# ESP32-H4 register map
Vendor: ESPRESSIF SYSTEMS (SHANGHAI) CO., LTD.; Series: ESP32 H-Series; File version: 1
CPU: RV32IMAC r0p0, little endian, no MPU, no FPU, 0 interrupt priority bits
Address unit: 32 bits
Registers are 32-bit, read-write, reset 0x0 unless marked. A register's access mark holds for its fields unless they carry their own. Offsets are from the block's base; [hi:lo] are bit positions.

## PMU — PMU Peripheral
Base 0x600B2400
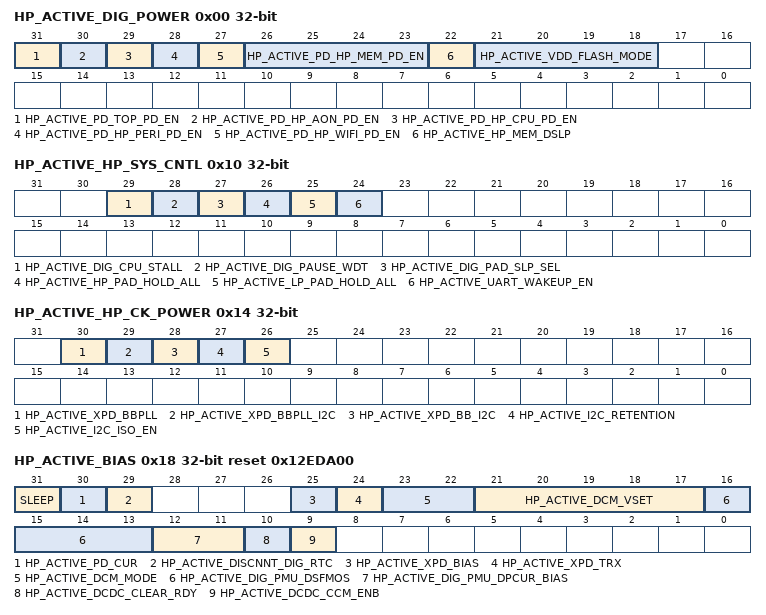
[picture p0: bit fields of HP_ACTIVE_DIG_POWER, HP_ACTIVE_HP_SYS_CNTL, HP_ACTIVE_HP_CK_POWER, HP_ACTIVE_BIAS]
0x00 HP_ACTIVE_DIG_POWER — need_des
  [31] HP_ACTIVE_PD_TOP_PD_EN — need_des
  [30] HP_ACTIVE_PD_HP_AON_PD_EN — need_des
  [29] HP_ACTIVE_PD_HP_CPU_PD_EN — need_des
  [28] HP_ACTIVE_PD_HP_PERI_PD_EN — need_des
  [27] HP_ACTIVE_PD_HP_WIFI_PD_EN — need_des
  [26:23] HP_ACTIVE_PD_HP_MEM_PD_EN — need_des
  [22] HP_ACTIVE_HP_MEM_DSLP — need_des
  [21:18] HP_ACTIVE_VDD_FLASH_MODE — need_des
0x04 HP_ACTIVE_ICG_HP_FUNC reset 0xFFFFFFFF — need_des
  [31:0] HP_ACTIVE_DIG_ICG_FUNC_EN
0x08 HP_ACTIVE_ICG_HP_APB reset 0xFFFFFFFF — need_des
  [31:0] HP_ACTIVE_DIG_ICG_APB_EN
0x0C HP_ACTIVE_ICG_MODEM — need_des
  [31:30] HP_ACTIVE_DIG_ICG_MODEM_CODE
0x10 HP_ACTIVE_HP_SYS_CNTL — need_des
  [29] HP_ACTIVE_DIG_CPU_STALL — need_des
  [28] HP_ACTIVE_DIG_PAUSE_WDT — need_des
  [27] HP_ACTIVE_DIG_PAD_SLP_SEL — need_des
  [26] HP_ACTIVE_HP_PAD_HOLD_ALL — need_des
  [25] HP_ACTIVE_LP_PAD_HOLD_ALL — need_des
  [24] HP_ACTIVE_UART_WAKEUP_EN — need_des
0x14 HP_ACTIVE_HP_CK_POWER — need_des
  [30] HP_ACTIVE_XPD_BBPLL — need_des
  [29] HP_ACTIVE_XPD_BBPLL_I2C — need_des
  [28] HP_ACTIVE_XPD_BB_I2C — need_des
  [27] HP_ACTIVE_I2C_RETENTION — need_des
  [26] HP_ACTIVE_I2C_ISO_EN — need_des
0x18 HP_ACTIVE_BIAS reset 0x12EDA00 — need_des
  [31] SLEEP — need_des
  [30] HP_ACTIVE_PD_CUR — need_des
  [29] HP_ACTIVE_DISCNNT_DIG_RTC — need_des
  [25] HP_ACTIVE_XPD_BIAS — need_des
  [24] HP_ACTIVE_XPD_TRX — need_des
  [23:22] HP_ACTIVE_DCM_MODE — need_des
  [21:17] HP_ACTIVE_DCM_VSET — need_des
  [16:13] HP_ACTIVE_DIG_PMU_DSFMOS — need_des
  [12:11] HP_ACTIVE_DIG_PMU_DPCUR_BIAS — need_des
  [10] HP_ACTIVE_DCDC_CLEAR_RDY — need_des
  [9] HP_ACTIVE_DCDC_CCM_ENB — need_des
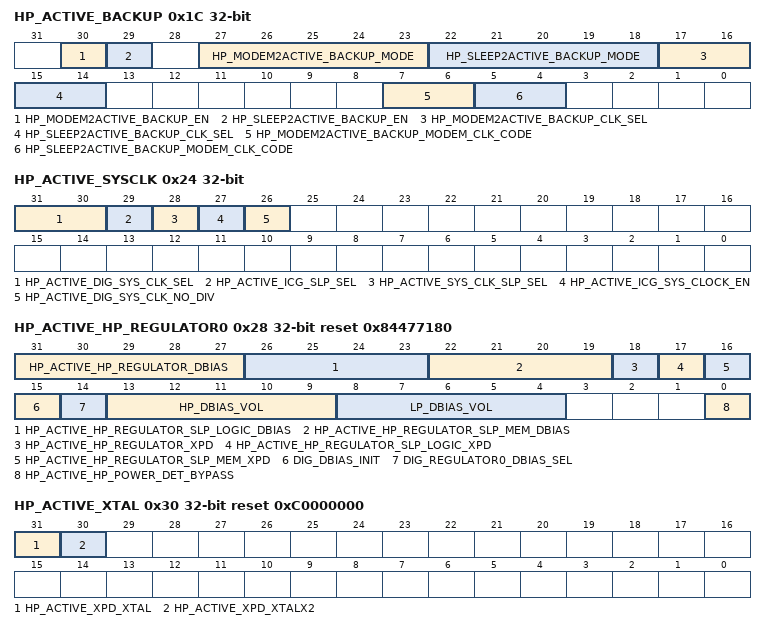
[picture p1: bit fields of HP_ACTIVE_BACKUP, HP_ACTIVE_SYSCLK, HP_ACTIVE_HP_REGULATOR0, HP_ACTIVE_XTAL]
0x1C HP_ACTIVE_BACKUP — need_des
  [30] HP_MODEM2ACTIVE_BACKUP_EN — need_des
  [29] HP_SLEEP2ACTIVE_BACKUP_EN — need_des
  [27:23] HP_MODEM2ACTIVE_BACKUP_MODE — need_des
  [22:18] HP_SLEEP2ACTIVE_BACKUP_MODE — need_des
  [17:16] HP_MODEM2ACTIVE_BACKUP_CLK_SEL — need_des
  [15:14] HP_SLEEP2ACTIVE_BACKUP_CLK_SEL — need_des
  [7:6] HP_MODEM2ACTIVE_BACKUP_MODEM_CLK_CODE — need_des
  [5:4] HP_SLEEP2ACTIVE_BACKUP_MODEM_CLK_CODE — need_des
0x20 HP_ACTIVE_BACKUP_CLK — need_des
  [31:0] HP_ACTIVE_BACKUP_ICG_FUNC_EN
0x24 HP_ACTIVE_SYSCLK — need_des
  [31:30] HP_ACTIVE_DIG_SYS_CLK_SEL — need_des
  [29] HP_ACTIVE_ICG_SLP_SEL — need_des
  [28] HP_ACTIVE_SYS_CLK_SLP_SEL — need_des
  [27] HP_ACTIVE_ICG_SYS_CLOCK_EN — need_des
  [26] HP_ACTIVE_DIG_SYS_CLK_NO_DIV — need_des
0x28 HP_ACTIVE_HP_REGULATOR0 access per field reset 0x84477180 — need_des
  [31:27] HP_ACTIVE_HP_REGULATOR_DBIAS rw — need_des
  [26:23] HP_ACTIVE_HP_REGULATOR_SLP_LOGIC_DBIAS rw — need_des
  [22:19] HP_ACTIVE_HP_REGULATOR_SLP_MEM_DBIAS rw — need_des
  [18] HP_ACTIVE_HP_REGULATOR_XPD rw — need_des
  [17] HP_ACTIVE_HP_REGULATOR_SLP_LOGIC_XPD rw — need_des
  [16] HP_ACTIVE_HP_REGULATOR_SLP_MEM_XPD rw — need_des
  [15] DIG_DBIAS_INIT wo — need_des
  [14] DIG_REGULATOR0_DBIAS_SEL rw — need_des
  [13:9] HP_DBIAS_VOL ro — need_des
  [8:4] LP_DBIAS_VOL ro — need_des
  [0] HP_ACTIVE_HP_POWER_DET_BYPASS rw — need_des
0x2C HP_ACTIVE_HP_REGULATOR1 reset 0x1000 — need_des
  [31:8] HP_ACTIVE_HP_REGULATOR_DRV_B
0x30 HP_ACTIVE_XTAL reset 0xC0000000 — need_des
  [31] HP_ACTIVE_XPD_XTAL — need_des
  [30] HP_ACTIVE_XPD_XTALX2 — need_des
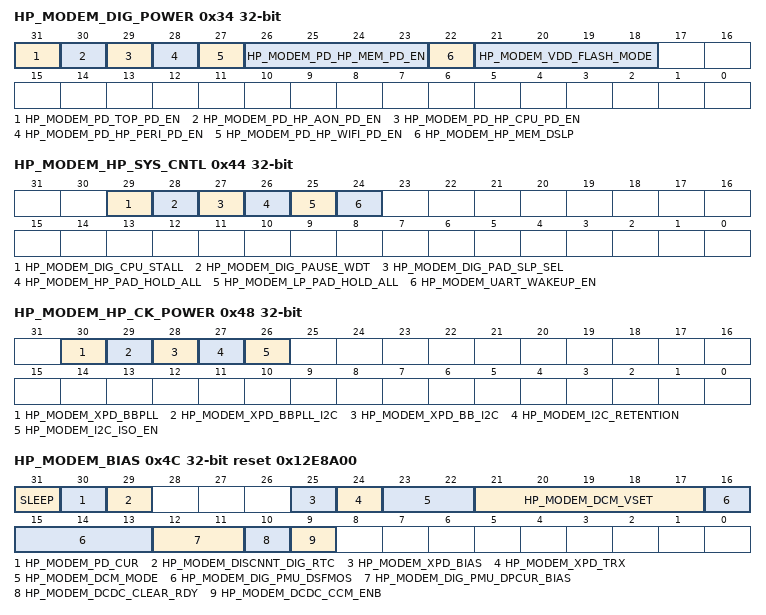
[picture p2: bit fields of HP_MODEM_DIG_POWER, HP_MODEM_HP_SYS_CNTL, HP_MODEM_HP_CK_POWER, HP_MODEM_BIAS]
0x34 HP_MODEM_DIG_POWER — need_des
  [31] HP_MODEM_PD_TOP_PD_EN — need_des
  [30] HP_MODEM_PD_HP_AON_PD_EN — need_des
  [29] HP_MODEM_PD_HP_CPU_PD_EN — need_des
  [28] HP_MODEM_PD_HP_PERI_PD_EN — need_des
  [27] HP_MODEM_PD_HP_WIFI_PD_EN — need_des
  [26:23] HP_MODEM_PD_HP_MEM_PD_EN — need_des
  [22] HP_MODEM_HP_MEM_DSLP — need_des
  [21:18] HP_MODEM_VDD_FLASH_MODE — need_des
0x38 HP_MODEM_ICG_HP_FUNC reset 0xFFFFFFFF — need_des
  [31:0] HP_MODEM_DIG_ICG_FUNC_EN
0x3C HP_MODEM_ICG_HP_APB reset 0xFFFFFFFF — need_des
  [31:0] HP_MODEM_DIG_ICG_APB_EN
0x40 HP_MODEM_ICG_MODEM — need_des
  [31:30] HP_MODEM_DIG_ICG_MODEM_CODE
0x44 HP_MODEM_HP_SYS_CNTL — need_des
  [29] HP_MODEM_DIG_CPU_STALL — need_des
  [28] HP_MODEM_DIG_PAUSE_WDT — need_des
  [27] HP_MODEM_DIG_PAD_SLP_SEL — need_des
  [26] HP_MODEM_HP_PAD_HOLD_ALL — need_des
  [25] HP_MODEM_LP_PAD_HOLD_ALL — need_des
  [24] HP_MODEM_UART_WAKEUP_EN — need_des
0x48 HP_MODEM_HP_CK_POWER — need_des
  [30] HP_MODEM_XPD_BBPLL — need_des
  [29] HP_MODEM_XPD_BBPLL_I2C — need_des
  [28] HP_MODEM_XPD_BB_I2C — need_des
  [27] HP_MODEM_I2C_RETENTION — need_des
  [26] HP_MODEM_I2C_ISO_EN — need_des
0x4C HP_MODEM_BIAS reset 0x12E8A00 — need_des
  [31] SLEEP — need_des
  [30] HP_MODEM_PD_CUR — need_des
  [29] HP_MODEM_DISCNNT_DIG_RTC — need_des
  [25] HP_MODEM_XPD_BIAS — need_des
  [24] HP_MODEM_XPD_TRX — need_des
  [23:22] HP_MODEM_DCM_MODE — need_des
  [21:17] HP_MODEM_DCM_VSET — need_des
  [16:13] HP_MODEM_DIG_PMU_DSFMOS — need_des
  [12:11] HP_MODEM_DIG_PMU_DPCUR_BIAS — need_des
  [10] HP_MODEM_DCDC_CLEAR_RDY — need_des
  [9] HP_MODEM_DCDC_CCM_ENB — need_des
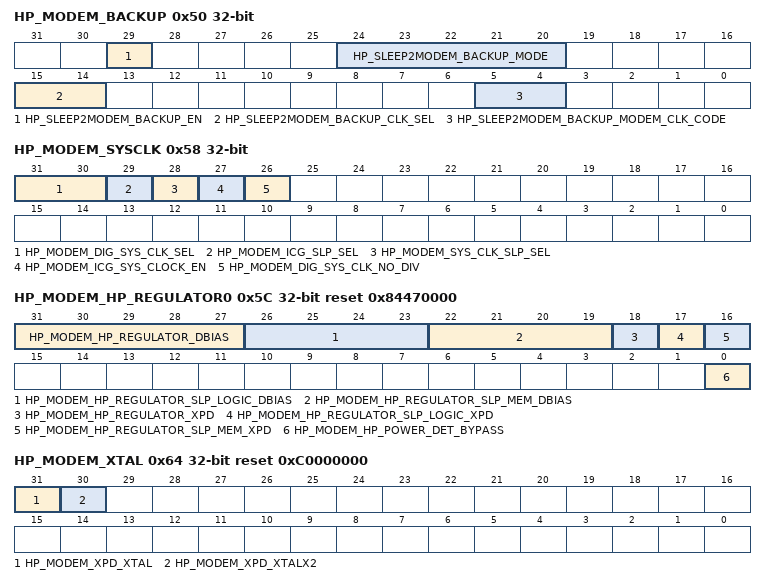
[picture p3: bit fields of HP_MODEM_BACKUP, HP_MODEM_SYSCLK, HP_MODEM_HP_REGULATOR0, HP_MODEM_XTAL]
0x50 HP_MODEM_BACKUP — need_des
  [29] HP_SLEEP2MODEM_BACKUP_EN — need_des
  [24:20] HP_SLEEP2MODEM_BACKUP_MODE — need_des
  [15:14] HP_SLEEP2MODEM_BACKUP_CLK_SEL — need_des
  [5:4] HP_SLEEP2MODEM_BACKUP_MODEM_CLK_CODE — need_des
0x54 HP_MODEM_BACKUP_CLK — need_des
  [31:0] HP_MODEM_BACKUP_ICG_FUNC_EN
0x58 HP_MODEM_SYSCLK — need_des
  [31:30] HP_MODEM_DIG_SYS_CLK_SEL — need_des
  [29] HP_MODEM_ICG_SLP_SEL — need_des
  [28] HP_MODEM_SYS_CLK_SLP_SEL — need_des
  [27] HP_MODEM_ICG_SYS_CLOCK_EN — need_des
  [26] HP_MODEM_DIG_SYS_CLK_NO_DIV — need_des
0x5C HP_MODEM_HP_REGULATOR0 reset 0x84470000 — need_des
  [31:27] HP_MODEM_HP_REGULATOR_DBIAS — need_des
  [26:23] HP_MODEM_HP_REGULATOR_SLP_LOGIC_DBIAS — need_des
  [22:19] HP_MODEM_HP_REGULATOR_SLP_MEM_DBIAS — need_des
  [18] HP_MODEM_HP_REGULATOR_XPD — need_des
  [17] HP_MODEM_HP_REGULATOR_SLP_LOGIC_XPD — need_des
  [16] HP_MODEM_HP_REGULATOR_SLP_MEM_XPD — need_des
  [0] HP_MODEM_HP_POWER_DET_BYPASS — need_des
0x60 HP_MODEM_HP_REGULATOR1 reset 0x1000 — need_des
  [31:8] HP_MODEM_HP_REGULATOR_DRV_B
0x64 HP_MODEM_XTAL reset 0xC0000000 — need_des
  [31] HP_MODEM_XPD_XTAL — need_des
  [30] HP_MODEM_XPD_XTALX2 — need_des
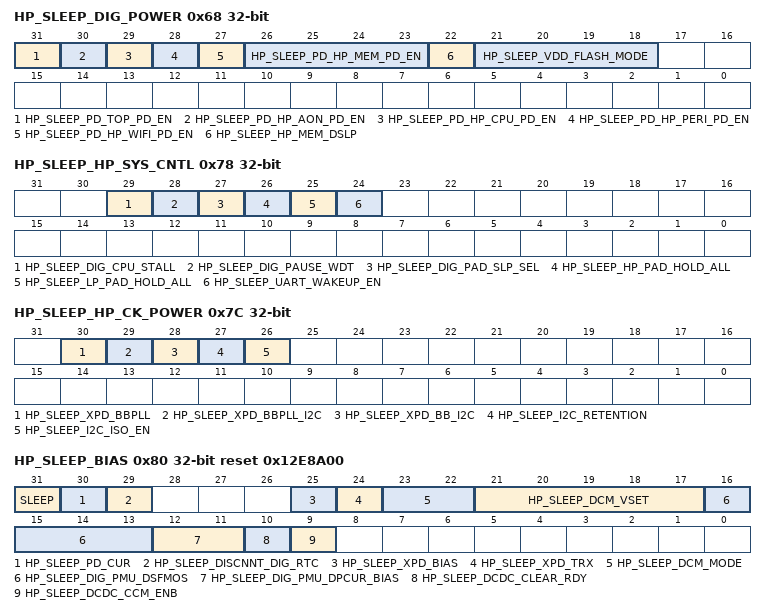
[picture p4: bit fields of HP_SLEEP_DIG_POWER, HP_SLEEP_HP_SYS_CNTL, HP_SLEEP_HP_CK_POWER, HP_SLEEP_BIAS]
0x68 HP_SLEEP_DIG_POWER — need_des
  [31] HP_SLEEP_PD_TOP_PD_EN — need_des
  [30] HP_SLEEP_PD_HP_AON_PD_EN — need_des
  [29] HP_SLEEP_PD_HP_CPU_PD_EN — need_des
  [28] HP_SLEEP_PD_HP_PERI_PD_EN — need_des
  [27] HP_SLEEP_PD_HP_WIFI_PD_EN — need_des
  [26:23] HP_SLEEP_PD_HP_MEM_PD_EN — need_des
  [22] HP_SLEEP_HP_MEM_DSLP — need_des
  [21:18] HP_SLEEP_VDD_FLASH_MODE — need_des
0x6C HP_SLEEP_ICG_HP_FUNC reset 0xFFFFFFFF — need_des
  [31:0] HP_SLEEP_DIG_ICG_FUNC_EN
0x70 HP_SLEEP_ICG_HP_APB reset 0xFFFFFFFF — need_des
  [31:0] HP_SLEEP_DIG_ICG_APB_EN
0x74 HP_SLEEP_ICG_MODEM — need_des
  [31:30] HP_SLEEP_DIG_ICG_MODEM_CODE
0x78 HP_SLEEP_HP_SYS_CNTL — need_des
  [29] HP_SLEEP_DIG_CPU_STALL — need_des
  [28] HP_SLEEP_DIG_PAUSE_WDT — need_des
  [27] HP_SLEEP_DIG_PAD_SLP_SEL — need_des
  [26] HP_SLEEP_HP_PAD_HOLD_ALL — need_des
  [25] HP_SLEEP_LP_PAD_HOLD_ALL — need_des
  [24] HP_SLEEP_UART_WAKEUP_EN — need_des
0x7C HP_SLEEP_HP_CK_POWER — need_des
  [30] HP_SLEEP_XPD_BBPLL — need_des
  [29] HP_SLEEP_XPD_BBPLL_I2C — need_des
  [28] HP_SLEEP_XPD_BB_I2C — need_des
  [27] HP_SLEEP_I2C_RETENTION — need_des
  [26] HP_SLEEP_I2C_ISO_EN — need_des
0x80 HP_SLEEP_BIAS reset 0x12E8A00 — need_des
  [31] SLEEP — need_des
  [30] HP_SLEEP_PD_CUR — need_des
  [29] HP_SLEEP_DISCNNT_DIG_RTC — need_des
  [25] HP_SLEEP_XPD_BIAS — need_des
  [24] HP_SLEEP_XPD_TRX — need_des
  [23:22] HP_SLEEP_DCM_MODE — need_des
  [21:17] HP_SLEEP_DCM_VSET — need_des
  [16:13] HP_SLEEP_DIG_PMU_DSFMOS — need_des
  [12:11] HP_SLEEP_DIG_PMU_DPCUR_BIAS — need_des
  [10] HP_SLEEP_DCDC_CLEAR_RDY — need_des
  [9] HP_SLEEP_DCDC_CCM_ENB — need_des
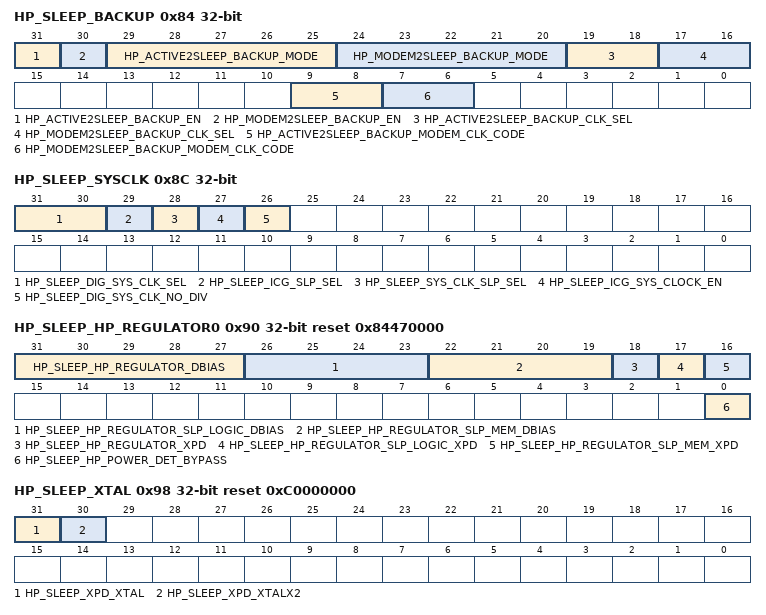
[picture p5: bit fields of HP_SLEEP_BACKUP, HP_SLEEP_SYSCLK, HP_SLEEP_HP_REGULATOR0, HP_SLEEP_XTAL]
0x84 HP_SLEEP_BACKUP — need_des
  [31] HP_ACTIVE2SLEEP_BACKUP_EN — need_des
  [30] HP_MODEM2SLEEP_BACKUP_EN — need_des
  [29:25] HP_ACTIVE2SLEEP_BACKUP_MODE — need_des
  [24:20] HP_MODEM2SLEEP_BACKUP_MODE — need_des
  [19:18] HP_ACTIVE2SLEEP_BACKUP_CLK_SEL — need_des
  [17:16] HP_MODEM2SLEEP_BACKUP_CLK_SEL — need_des
  [9:8] HP_ACTIVE2SLEEP_BACKUP_MODEM_CLK_CODE — need_des
  [7:6] HP_MODEM2SLEEP_BACKUP_MODEM_CLK_CODE — need_des
0x88 HP_SLEEP_BACKUP_CLK — need_des
  [31:0] HP_SLEEP_BACKUP_ICG_FUNC_EN
0x8C HP_SLEEP_SYSCLK — need_des
  [31:30] HP_SLEEP_DIG_SYS_CLK_SEL — need_des
  [29] HP_SLEEP_ICG_SLP_SEL — need_des
  [28] HP_SLEEP_SYS_CLK_SLP_SEL — need_des
  [27] HP_SLEEP_ICG_SYS_CLOCK_EN — need_des
  [26] HP_SLEEP_DIG_SYS_CLK_NO_DIV — need_des
0x90 HP_SLEEP_HP_REGULATOR0 reset 0x84470000 — need_des
  [31:27] HP_SLEEP_HP_REGULATOR_DBIAS — need_des
  [26:23] HP_SLEEP_HP_REGULATOR_SLP_LOGIC_DBIAS — need_des
  [22:19] HP_SLEEP_HP_REGULATOR_SLP_MEM_DBIAS — need_des
  [18] HP_SLEEP_HP_REGULATOR_XPD — need_des
  [17] HP_SLEEP_HP_REGULATOR_SLP_LOGIC_XPD — need_des
  [16] HP_SLEEP_HP_REGULATOR_SLP_MEM_XPD — need_des
  [0] HP_SLEEP_HP_POWER_DET_BYPASS — need_des
0x94 HP_SLEEP_HP_REGULATOR1 reset 0x1000 — need_des
  [31:8] HP_SLEEP_HP_REGULATOR_DRV_B
0x98 HP_SLEEP_XTAL reset 0xC0000000 — need_des
  [31] HP_SLEEP_XPD_XTAL — need_des
  [30] HP_SLEEP_XPD_XTALX2 — need_des
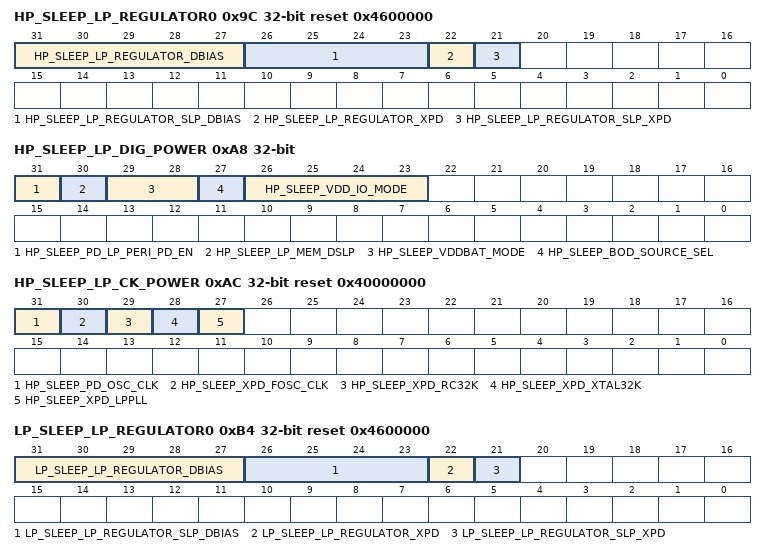
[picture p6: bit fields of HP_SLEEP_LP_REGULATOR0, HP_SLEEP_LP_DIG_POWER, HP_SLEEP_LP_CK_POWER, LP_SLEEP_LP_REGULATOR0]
0x9C HP_SLEEP_LP_REGULATOR0 reset 0x4600000 — need_des
  [31:27] HP_SLEEP_LP_REGULATOR_DBIAS — need_des
  [26:23] HP_SLEEP_LP_REGULATOR_SLP_DBIAS — need_des
  [22] HP_SLEEP_LP_REGULATOR_XPD — need_des
  [21] HP_SLEEP_LP_REGULATOR_SLP_XPD — need_des
0xA0 HP_SLEEP_LP_REGULATOR1 — need_des
  [31:28] HP_SLEEP_LP_REGULATOR_DRV_B
0xA4 HP_SLEEP_LP_DCDC_RESERVE wo — need_des
0xA8 HP_SLEEP_LP_DIG_POWER — need_des
  [31] HP_SLEEP_PD_LP_PERI_PD_EN — need_des
  [30] HP_SLEEP_LP_MEM_DSLP — need_des
  [29:28] HP_SLEEP_VDDBAT_MODE — need_des
  [27] HP_SLEEP_BOD_SOURCE_SEL — need_des
  [26:23] HP_SLEEP_VDD_IO_MODE — need_des
0xAC HP_SLEEP_LP_CK_POWER reset 0x40000000 — need_des
  [31] HP_SLEEP_PD_OSC_CLK — need_des
  [30] HP_SLEEP_XPD_FOSC_CLK — need_des
  [29] HP_SLEEP_XPD_RC32K — need_des
  [28] HP_SLEEP_XPD_XTAL32K — need_des
  [27] HP_SLEEP_XPD_LPPLL — need_des
0xB0 LP_SLEEP_LP_BIAS_RESERVE wo — need_des
0xB4 LP_SLEEP_LP_REGULATOR0 reset 0x4600000 — need_des
  [31:27] LP_SLEEP_LP_REGULATOR_DBIAS — need_des
  [26:23] LP_SLEEP_LP_REGULATOR_SLP_DBIAS — need_des
  [22] LP_SLEEP_LP_REGULATOR_XPD — need_des
  [21] LP_SLEEP_LP_REGULATOR_SLP_XPD — need_des
0xB8 LP_SLEEP_LP_REGULATOR1 — need_des
  [31:28] LP_SLEEP_LP_REGULATOR_DRV_B
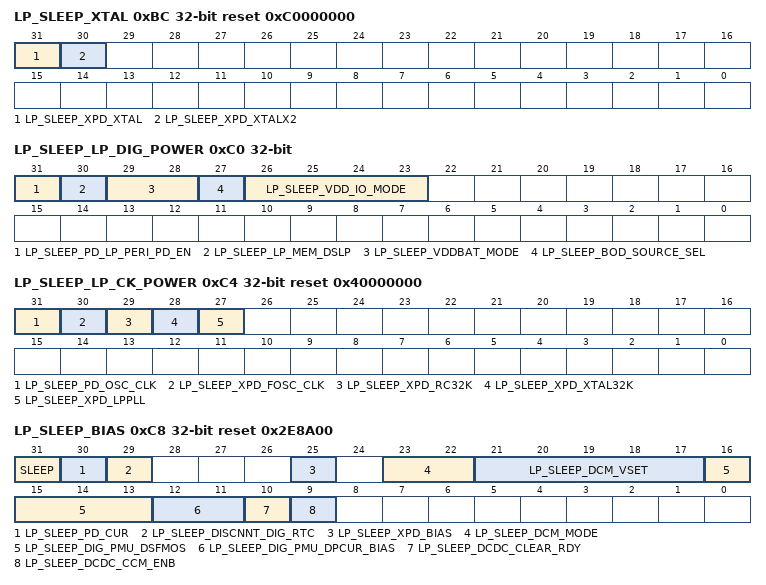
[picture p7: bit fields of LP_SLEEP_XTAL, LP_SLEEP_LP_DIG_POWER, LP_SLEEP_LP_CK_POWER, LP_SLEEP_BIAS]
0xBC LP_SLEEP_XTAL reset 0xC0000000 — need_des
  [31] LP_SLEEP_XPD_XTAL — need_des
  [30] LP_SLEEP_XPD_XTALX2 — need_des
0xC0 LP_SLEEP_LP_DIG_POWER — need_des
  [31] LP_SLEEP_PD_LP_PERI_PD_EN — need_des
  [30] LP_SLEEP_LP_MEM_DSLP — need_des
  [29:28] LP_SLEEP_VDDBAT_MODE — need_des
  [27] LP_SLEEP_BOD_SOURCE_SEL — need_des
  [26:23] LP_SLEEP_VDD_IO_MODE — need_des
0xC4 LP_SLEEP_LP_CK_POWER reset 0x40000000 — need_des
  [31] LP_SLEEP_PD_OSC_CLK — need_des
  [30] LP_SLEEP_XPD_FOSC_CLK — need_des
  [29] LP_SLEEP_XPD_RC32K — need_des
  [28] LP_SLEEP_XPD_XTAL32K — need_des
  [27] LP_SLEEP_XPD_LPPLL — need_des
0xC8 LP_SLEEP_BIAS reset 0x2E8A00 — need_des
  [31] SLEEP — need_des
  [30] LP_SLEEP_PD_CUR — need_des
  [29] LP_SLEEP_DISCNNT_DIG_RTC — need_des
  [25] LP_SLEEP_XPD_BIAS — need_des
  [23:22] LP_SLEEP_DCM_MODE — need_des
  [21:17] LP_SLEEP_DCM_VSET — need_des
  [16:13] LP_SLEEP_DIG_PMU_DSFMOS — need_des
  [12:11] LP_SLEEP_DIG_PMU_DPCUR_BIAS — need_des
  [10] LP_SLEEP_DCDC_CLEAR_RDY — need_des
  [9] LP_SLEEP_DCDC_CCM_ENB — need_des
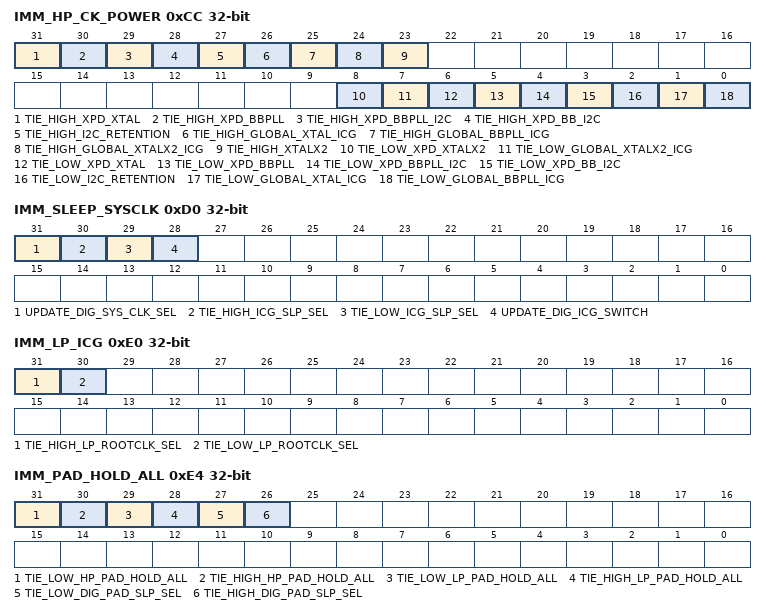
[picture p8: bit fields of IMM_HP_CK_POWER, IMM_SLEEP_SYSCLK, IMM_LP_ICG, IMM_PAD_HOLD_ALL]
0xCC IMM_HP_CK_POWER wo — need_des
  [31] TIE_HIGH_XPD_XTAL — need_des
  [30] TIE_HIGH_XPD_BBPLL — need_des
  [29] TIE_HIGH_XPD_BBPLL_I2C — need_des
  [28] TIE_HIGH_XPD_BB_I2C — need_des
  [27] TIE_HIGH_I2C_RETENTION — need_des
  [26] TIE_HIGH_GLOBAL_XTAL_ICG — need_des
  [25] TIE_HIGH_GLOBAL_BBPLL_ICG — need_des
  [24] TIE_HIGH_GLOBAL_XTALX2_ICG — need_des
  [23] TIE_HIGH_XTALX2 — need_des
  [8] TIE_LOW_XPD_XTALX2 — need_des
  [7] TIE_LOW_GLOBAL_XTALX2_ICG — need_des
  [6] TIE_LOW_XPD_XTAL — need_des
  [5] TIE_LOW_XPD_BBPLL — need_des
  [4] TIE_LOW_XPD_BBPLL_I2C — need_des
  [3] TIE_LOW_XPD_BB_I2C — need_des
  [2] TIE_LOW_I2C_RETENTION — need_des
  [1] TIE_LOW_GLOBAL_XTAL_ICG — need_des
  [0] TIE_LOW_GLOBAL_BBPLL_ICG — need_des
0xD0 IMM_SLEEP_SYSCLK wo — need_des
  [31] UPDATE_DIG_SYS_CLK_SEL — need_des
  [30] TIE_HIGH_ICG_SLP_SEL — need_des
  [29] TIE_LOW_ICG_SLP_SEL — need_des
  [28] UPDATE_DIG_ICG_SWITCH — need_des
0xD4 IMM_HP_FUNC_ICG wo — need_des
  [31] UPDATE_DIG_ICG_FUNC_EN
0xD8 IMM_HP_APB_ICG wo — need_des
  [31] UPDATE_DIG_ICG_APB_EN
0xDC IMM_MODEM_ICG wo — need_des
  [31] UPDATE_DIG_ICG_MODEM_EN
0xE0 IMM_LP_ICG wo — need_des
  [31] TIE_HIGH_LP_ROOTCLK_SEL — need_des
  [30] TIE_LOW_LP_ROOTCLK_SEL — need_des
0xE4 IMM_PAD_HOLD_ALL wo — need_des
  [31] TIE_LOW_HP_PAD_HOLD_ALL — need_des
  [30] TIE_HIGH_HP_PAD_HOLD_ALL — need_des
  [29] TIE_LOW_LP_PAD_HOLD_ALL — need_des
  [28] TIE_HIGH_LP_PAD_HOLD_ALL — need_des
  [27] TIE_LOW_DIG_PAD_SLP_SEL — need_des
  [26] TIE_HIGH_DIG_PAD_SLP_SEL — need_des
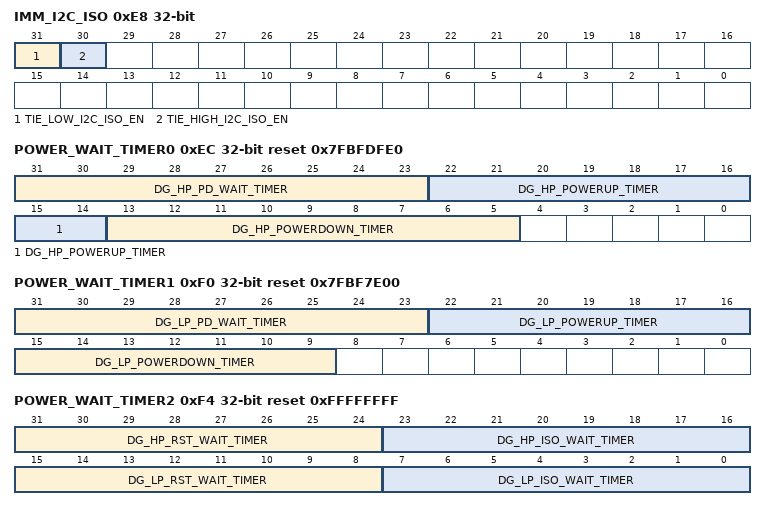
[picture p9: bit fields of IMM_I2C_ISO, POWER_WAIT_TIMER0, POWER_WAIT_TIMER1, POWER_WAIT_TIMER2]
0xE8 IMM_I2C_ISO wo — need_des
  [31] TIE_LOW_I2C_ISO_EN — need_des
  [30] TIE_HIGH_I2C_ISO_EN — need_des
0xEC POWER_WAIT_TIMER0 reset 0x7FBFDFE0 — need_des
  [31:23] DG_HP_PD_WAIT_TIMER — need_des
  [22:14] DG_HP_POWERUP_TIMER — need_des
  [13:5] DG_HP_POWERDOWN_TIMER — need_des
0xF0 POWER_WAIT_TIMER1 reset 0x7FBF7E00 — need_des
  [31:23] DG_LP_PD_WAIT_TIMER — need_des
  [22:16] DG_LP_POWERUP_TIMER — need_des
  [15:9] DG_LP_POWERDOWN_TIMER — need_des
0xF4 POWER_WAIT_TIMER2 reset 0xFFFFFFFF — need_des
  [31:24] DG_HP_RST_WAIT_TIMER — need_des
  [23:16] DG_HP_ISO_WAIT_TIMER — need_des
  [15:8] DG_LP_RST_WAIT_TIMER — need_des
  [7:0] DG_LP_ISO_WAIT_TIMER — need_des
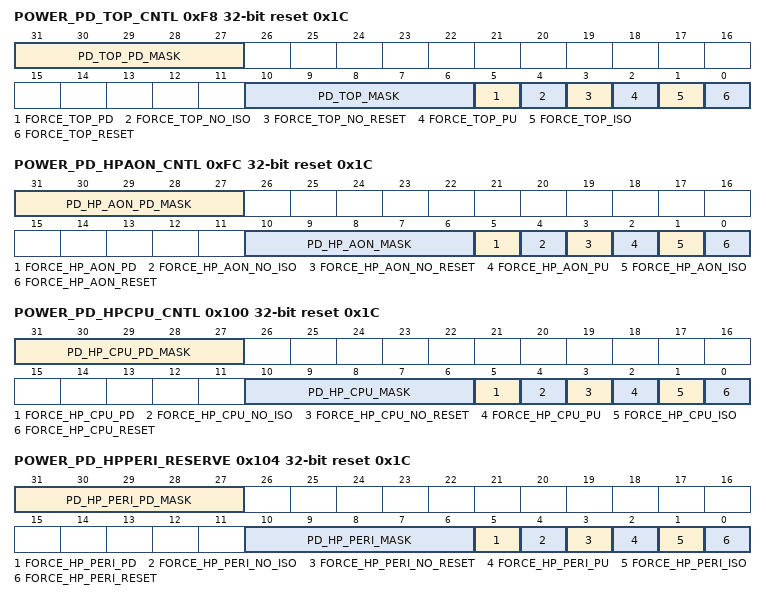
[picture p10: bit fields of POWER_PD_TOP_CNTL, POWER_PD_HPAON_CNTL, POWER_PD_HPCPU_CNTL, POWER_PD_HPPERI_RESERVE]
0xF8 POWER_PD_TOP_CNTL reset 0x1C — need_des
  [31:27] PD_TOP_PD_MASK — need_des
  [10:6] PD_TOP_MASK — need_des
  [5] FORCE_TOP_PD — need_des
  [4] FORCE_TOP_NO_ISO — need_des
  [3] FORCE_TOP_NO_RESET — need_des
  [2] FORCE_TOP_PU — need_des
  [1] FORCE_TOP_ISO — need_des
  [0] FORCE_TOP_RESET — need_des
0xFC POWER_PD_HPAON_CNTL reset 0x1C — need_des
  [31:27] PD_HP_AON_PD_MASK — need_des
  [10:6] PD_HP_AON_MASK — need_des
  [5] FORCE_HP_AON_PD — need_des
  [4] FORCE_HP_AON_NO_ISO — need_des
  [3] FORCE_HP_AON_NO_RESET — need_des
  [2] FORCE_HP_AON_PU — need_des
  [1] FORCE_HP_AON_ISO — need_des
  [0] FORCE_HP_AON_RESET — need_des
0x100 POWER_PD_HPCPU_CNTL reset 0x1C — need_des
  [31:27] PD_HP_CPU_PD_MASK — need_des
  [10:6] PD_HP_CPU_MASK — need_des
  [5] FORCE_HP_CPU_PD — need_des
  [4] FORCE_HP_CPU_NO_ISO — need_des
  [3] FORCE_HP_CPU_NO_RESET — need_des
  [2] FORCE_HP_CPU_PU — need_des
  [1] FORCE_HP_CPU_ISO — need_des
  [0] FORCE_HP_CPU_RESET — need_des
0x104 POWER_PD_HPPERI_RESERVE reset 0x1C — need_des
  [31:27] PD_HP_PERI_PD_MASK — need_des
  [10:6] PD_HP_PERI_MASK — need_des
  [5] FORCE_HP_PERI_PD — need_des
  [4] FORCE_HP_PERI_NO_ISO — need_des
  [3] FORCE_HP_PERI_NO_RESET — need_des
  [2] FORCE_HP_PERI_PU — need_des
  [1] FORCE_HP_PERI_ISO — need_des
  [0] FORCE_HP_PERI_RESET — need_des
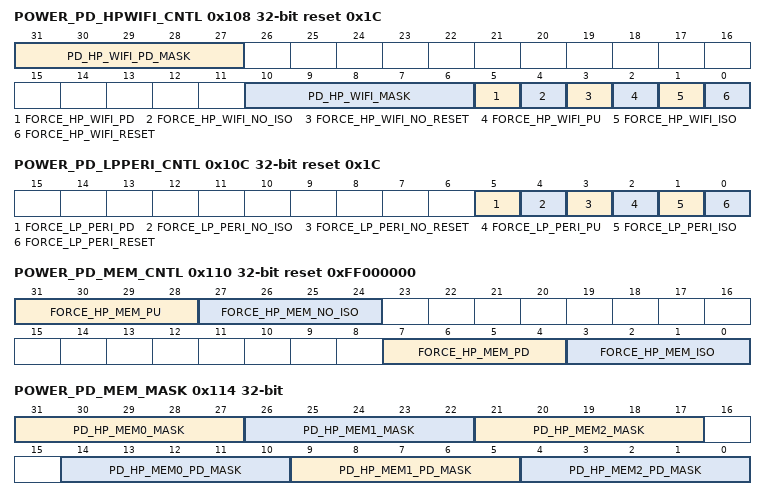
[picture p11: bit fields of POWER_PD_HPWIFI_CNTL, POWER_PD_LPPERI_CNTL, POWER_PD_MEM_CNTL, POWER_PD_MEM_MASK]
0x108 POWER_PD_HPWIFI_CNTL reset 0x1C — need_des
  [31:27] PD_HP_WIFI_PD_MASK — need_des
  [10:6] PD_HP_WIFI_MASK — need_des
  [5] FORCE_HP_WIFI_PD — need_des
  [4] FORCE_HP_WIFI_NO_ISO — need_des
  [3] FORCE_HP_WIFI_NO_RESET — need_des
  [2] FORCE_HP_WIFI_PU — need_des
  [1] FORCE_HP_WIFI_ISO — need_des
  [0] FORCE_HP_WIFI_RESET — need_des
0x10C POWER_PD_LPPERI_CNTL reset 0x1C — need_des
  [5] FORCE_LP_PERI_PD — need_des
  [4] FORCE_LP_PERI_NO_ISO — need_des
  [3] FORCE_LP_PERI_NO_RESET — need_des
  [2] FORCE_LP_PERI_PU — need_des
  [1] FORCE_LP_PERI_ISO — need_des
  [0] FORCE_LP_PERI_RESET — need_des
0x110 POWER_PD_MEM_CNTL reset 0xFF000000 — need_des
  [31:28] FORCE_HP_MEM_PU — need_des
  [27:24] FORCE_HP_MEM_NO_ISO — need_des
  [7:4] FORCE_HP_MEM_PD — need_des
  [3:0] FORCE_HP_MEM_ISO — need_des
0x114 POWER_PD_MEM_MASK — need_des
  [31:27] PD_HP_MEM0_MASK — need_des
  [26:22] PD_HP_MEM1_MASK — need_des
  [21:17] PD_HP_MEM2_MASK — need_des
  [14:10] PD_HP_MEM0_PD_MASK — need_des
  [9:5] PD_HP_MEM1_PD_MASK — need_des
  [4:0] PD_HP_MEM2_PD_MASK — need_des
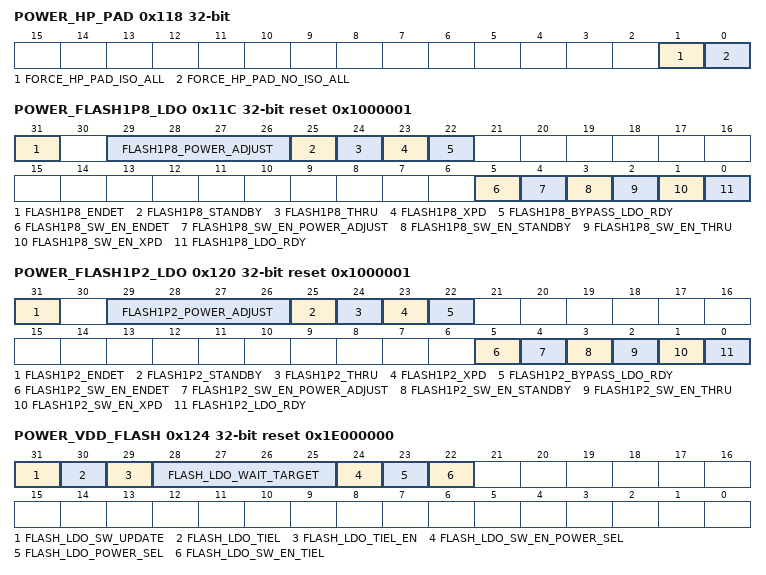
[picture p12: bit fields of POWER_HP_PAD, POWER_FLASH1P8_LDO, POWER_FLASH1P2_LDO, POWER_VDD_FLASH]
0x118 POWER_HP_PAD — need_des
  [1] FORCE_HP_PAD_ISO_ALL — need_des
  [0] FORCE_HP_PAD_NO_ISO_ALL — need_des
0x11C POWER_FLASH1P8_LDO access per field reset 0x1000001 — need_des
  [31] FLASH1P8_ENDET rw — need_des
  [29:26] FLASH1P8_POWER_ADJUST rw — need_des
  [25] FLASH1P8_STANDBY rw — need_des
  [24] FLASH1P8_THRU rw — need_des
  [23] FLASH1P8_XPD rw — need_des
  [22] FLASH1P8_BYPASS_LDO_RDY rw — need_des
  [5] FLASH1P8_SW_EN_ENDET rw — need_des
  [4] FLASH1P8_SW_EN_POWER_ADJUST rw — need_des
  [3] FLASH1P8_SW_EN_STANDBY rw — need_des
  [2] FLASH1P8_SW_EN_THRU rw — need_des
  [1] FLASH1P8_SW_EN_XPD rw — need_des
  [0] FLASH1P8_LDO_RDY ro — need_des
0x120 POWER_FLASH1P2_LDO access per field reset 0x1000001 — need_des
  [31] FLASH1P2_ENDET rw — need_des
  [29:26] FLASH1P2_POWER_ADJUST rw — need_des
  [25] FLASH1P2_STANDBY rw — need_des
  [24] FLASH1P2_THRU rw — need_des
  [23] FLASH1P2_XPD rw — need_des
  [22] FLASH1P2_BYPASS_LDO_RDY rw — need_des
  [5] FLASH1P2_SW_EN_ENDET rw — need_des
  [4] FLASH1P2_SW_EN_POWER_ADJUST rw — need_des
  [3] FLASH1P2_SW_EN_STANDBY rw — need_des
  [2] FLASH1P2_SW_EN_THRU rw — need_des
  [1] FLASH1P2_SW_EN_XPD rw — need_des
  [0] FLASH1P2_LDO_RDY ro — need_des
0x124 POWER_VDD_FLASH access per field reset 0x1E000000 — need_des
  [31] FLASH_LDO_SW_UPDATE wo — need_des
  [30] FLASH_LDO_TIEL rw — need_des
  [29] FLASH_LDO_TIEL_EN rw — need_des
  [28:25] FLASH_LDO_WAIT_TARGET rw — need_des
  [24] FLASH_LDO_SW_EN_POWER_SEL rw — need_des
  [23] FLASH_LDO_POWER_SEL rw — need_des
  [22] FLASH_LDO_SW_EN_TIEL rw — need_des
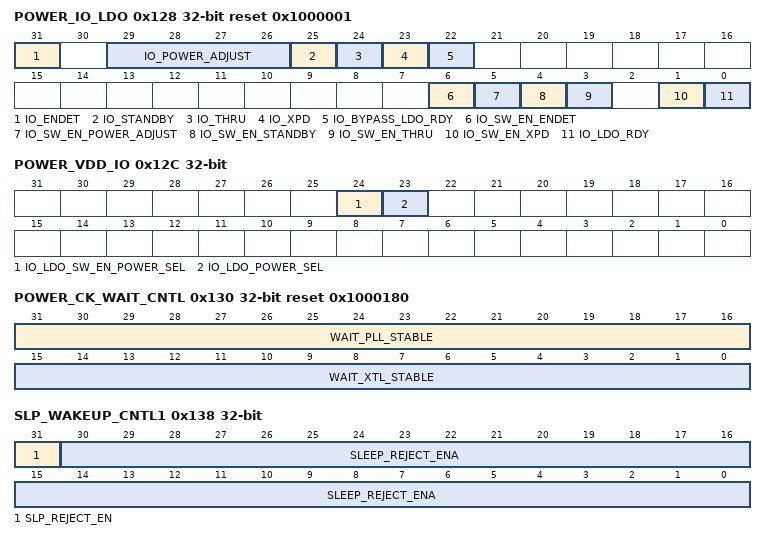
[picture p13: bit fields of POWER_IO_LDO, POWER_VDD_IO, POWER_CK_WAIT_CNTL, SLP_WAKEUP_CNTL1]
0x128 POWER_IO_LDO access per field reset 0x1000001 — need_des
  [31] IO_ENDET rw — need_des
  [29:26] IO_POWER_ADJUST rw — need_des
  [25] IO_STANDBY rw — need_des
  [24] IO_THRU rw — need_des
  [23] IO_XPD rw — need_des
  [22] IO_BYPASS_LDO_RDY rw — need_des
  [6] IO_SW_EN_ENDET rw — need_des
  [5] IO_SW_EN_POWER_ADJUST rw — need_des
  [4] IO_SW_EN_STANDBY rw — need_des
  [3] IO_SW_EN_THRU rw — need_des
  [1] IO_SW_EN_XPD rw — need_des
  [0] IO_LDO_RDY ro — need_des
0x12C POWER_VDD_IO — need_des
  [24] IO_LDO_SW_EN_POWER_SEL — need_des
  [23] IO_LDO_POWER_SEL — need_des
0x130 POWER_CK_WAIT_CNTL reset 0x1000180 — need_des
  [31:16] WAIT_PLL_STABLE — need_des
  [15:0] WAIT_XTL_STABLE — need_des
0x134 SLP_WAKEUP_CNTL0 wo — need_des
  [31] SLEEP_REQ
0x138 SLP_WAKEUP_CNTL1 — need_des
  [31] SLP_REJECT_EN — need_des
  [30:0] SLEEP_REJECT_ENA — need_des
0x13C SLP_WAKEUP_CNTL2 — need_des
  [31:0] WAKEUP_ENA
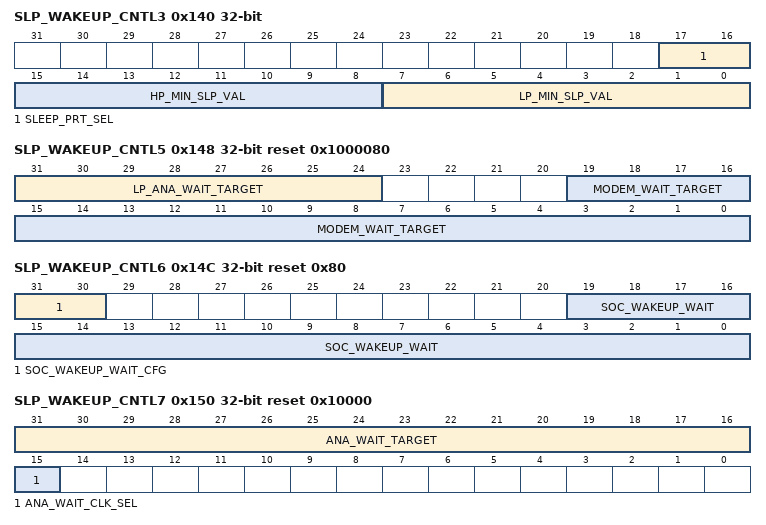
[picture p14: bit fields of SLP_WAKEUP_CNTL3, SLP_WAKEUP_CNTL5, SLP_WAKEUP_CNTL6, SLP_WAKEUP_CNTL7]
0x140 SLP_WAKEUP_CNTL3 — need_des
  [17:16] SLEEP_PRT_SEL — need_des
  [15:8] HP_MIN_SLP_VAL — need_des
  [7:0] LP_MIN_SLP_VAL — need_des
0x144 SLP_WAKEUP_CNTL4 wo — need_des
  [31] SLP_REJECT_CAUSE_CLR
0x148 SLP_WAKEUP_CNTL5 reset 0x1000080 — need_des
  [31:24] LP_ANA_WAIT_TARGET — need_des
  [19:0] MODEM_WAIT_TARGET — need_des
0x14C SLP_WAKEUP_CNTL6 reset 0x80 — need_des
  [31:30] SOC_WAKEUP_WAIT_CFG — need_des
  [19:0] SOC_WAKEUP_WAIT — need_des
0x150 SLP_WAKEUP_CNTL7 reset 0x10000 — need_des
  [31:16] ANA_WAIT_TARGET — need_des
  [15] ANA_WAIT_CLK_SEL — need_des
0x154 SLP_WAKEUP_STATUS0 ro — need_des
  [31:0] WAKEUP_CAUSE
0x158 SLP_WAKEUP_STATUS1 ro — need_des
  [31:0] REJECT_CAUSE
0x15C HP_CK_POWERON reset 0x32 — need_des
  [7:0] I2C_POR_WAIT_TARGET
0x160 HP_CK_CNTL reset 0xA0A — need_des
  [15:8] SWITCH_ICG_CNTL_WAIT — need_des
  [7:0] MODIFY_ICG_CNTL_WAIT — need_des
0x164 POR_STATUS ro — need_des
  [31] POR_DONE
0x168 RF_PWC reset 0x8000000 — need_des
  [31] XPD_FORCE_RFPLL — need_des
  [30] XPD_RFPLL — need_des
  [29] XPD_RFRX_I2C — need_des
  [28] XPD_RFTX_I2C — need_des
  [27] XPD_PERIF_I2C — need_des
  [26] XPD_FORCE_RFTX — need_des
0x16C VDDBAT_CFG access per field — need_des
  [31] VDDBAT_SW_UPDATE wo — need_des
  [1:0] VDDBAT_MODE ro — need_des
0x170 BACKUP_CFG reset 0x80000000 — need_des
  [31] BACKUP_SYS_CLK_NO_DIV
0x174 INT_RAW — need_des
  [31] SOC_WAKEUP_INT_RAW — need_des
  [30] SOC_SLEEP_REJECT_INT_RAW — need_des
  [29] SW_INT_RAW — need_des
  [28] SDIO_IDLE_INT_RAW — need_des
  [27] LP_CPU_EXC_INT_RAW — need_des
0x178 HP_INT_ST ro — need_des
  [31] SOC_WAKEUP_INT_ST — need_des
  [30] SOC_SLEEP_REJECT_INT_ST — need_des
  [29] SW_INT_ST — need_des
  [28] SDIO_IDLE_INT_ST — need_des
  [27] LP_CPU_EXC_INT_ST — need_des
0x17C HP_INT_ENA — need_des
  [31] SOC_WAKEUP_INT_ENA — need_des
  [30] SOC_SLEEP_REJECT_INT_ENA — need_des
  [29] SW_INT_ENA — need_des
  [28] SDIO_IDLE_INT_ENA — need_des
  [27] LP_CPU_EXC_INT_ENA — need_des
0x180 HP_INT_CLR wo — need_des
  [31] SOC_WAKEUP_INT_CLR — need_des
  [30] SOC_SLEEP_REJECT_INT_CLR — need_des
  [29] SW_INT_CLR — need_des
  [28] SDIO_IDLE_INT_CLR — need_des
  [27] LP_CPU_EXC_INT_CLR — need_des
0x184 LP_INT_RAW — need_des
  [31] HP_SW_TRIGGER_INT_RAW — need_des
  [30] ACTIVE_SWITCH_SLEEP_START_INT_RAW — need_des
  [29] MODEM_SWITCH_SLEEP_START_INT_RAW — need_des
  [28] SLEEP_SWITCH_MODEM_START_INT_RAW — need_des
  [27] SLEEP_SWITCH_ACTIVE_START_INT_RAW — need_des
  [26] MODEM_SWITCH_ACTIVE_START_INT_RAW — need_des
  [25] ACTIVE_SWITCH_SLEEP_END_INT_RAW — need_des
  [24] MODEM_SWITCH_SLEEP_END_INT_RAW — need_des
  [23] SLEEP_SWITCH_MODEM_END_INT_RAW — need_des
  [22] SLEEP_SWITCH_ACTIVE_END_INT_RAW — need_des
  [21] MODEM_SWITCH_ACTIVE_END_INT_RAW — need_des
  [20] LP_CPU_WAKEUP_INT_RAW — need_des
0x188 LP_INT_ST ro — need_des
  [31] HP_SW_TRIGGER_INT_ST — need_des
  [30] ACTIVE_SWITCH_SLEEP_START_INT_ST — need_des
  [29] MODEM_SWITCH_SLEEP_START_INT_ST — need_des
  [28] SLEEP_SWITCH_MODEM_START_INT_ST — need_des
  [27] SLEEP_SWITCH_ACTIVE_START_INT_ST — need_des
  [26] MODEM_SWITCH_ACTIVE_START_INT_ST — need_des
  [25] ACTIVE_SWITCH_SLEEP_END_INT_ST — need_des
  [24] MODEM_SWITCH_SLEEP_END_INT_ST — need_des
  [23] SLEEP_SWITCH_MODEM_END_INT_ST — need_des
  [22] SLEEP_SWITCH_ACTIVE_END_INT_ST — need_des
  [21] MODEM_SWITCH_ACTIVE_END_INT_ST — need_des
  [20] LP_CPU_WAKEUP_INT_ST — need_des
0x18C LP_INT_ENA — need_des
  [31] HP_SW_TRIGGER_INT_ENA — need_des
  [30] ACTIVE_SWITCH_SLEEP_START_INT_ENA — need_des
  [29] MODEM_SWITCH_SLEEP_START_INT_ENA — need_des
  [28] SLEEP_SWITCH_MODEM_START_INT_ENA — need_des
  [27] SLEEP_SWITCH_ACTIVE_START_INT_ENA — need_des
  [26] MODEM_SWITCH_ACTIVE_START_INT_ENA — need_des
  [25] ACTIVE_SWITCH_SLEEP_END_INT_ENA — need_des
  [24] MODEM_SWITCH_SLEEP_END_INT_ENA — need_des
  [23] SLEEP_SWITCH_MODEM_END_INT_ENA — need_des
  [22] SLEEP_SWITCH_ACTIVE_END_INT_ENA — need_des
  [21] MODEM_SWITCH_ACTIVE_END_INT_ENA — need_des
  [20] LP_CPU_WAKEUP_INT_ENA — need_des
0x190 LP_INT_CLR wo — need_des
  [31] HP_SW_TRIGGER_INT_CLR — need_des
  [30] ACTIVE_SWITCH_SLEEP_START_INT_CLR — need_des
  [29] MODEM_SWITCH_SLEEP_START_INT_CLR — need_des
  [28] SLEEP_SWITCH_MODEM_START_INT_CLR — need_des
  [27] SLEEP_SWITCH_ACTIVE_START_INT_CLR — need_des
  [26] MODEM_SWITCH_ACTIVE_START_INT_CLR — need_des
  [25] ACTIVE_SWITCH_SLEEP_END_INT_CLR — need_des
  [24] MODEM_SWITCH_SLEEP_END_INT_CLR — need_des
  [23] SLEEP_SWITCH_MODEM_END_INT_CLR — need_des
  [22] SLEEP_SWITCH_ACTIVE_END_INT_CLR — need_des
  [21] MODEM_SWITCH_ACTIVE_END_INT_CLR — need_des
  [20] LP_CPU_WAKEUP_INT_CLR — need_des
0x194 LP_CPU_PWR0 access per field reset 0x1FF00000 — need_des
  [31] LP_CPU_SLP_BYPASS_INTR_EN rw — need_des
  [30] LP_CPU_SLP_RESET_EN rw — need_des
  [29] LP_CPU_SLP_STALL_EN rw — need_des
  [28:21] LP_CPU_SLP_STALL_WAIT rw — need_des
  [20] LP_CPU_SLP_STALL_FLAG_EN rw — need_des
  [19] LP_CPU_SLP_WAITI_FLAG_EN rw — need_des
  [18] LP_CPU_FORCE_STALL rw — need_des
  [1] LP_CPU_STALL_RDY ro — need_des
  [0] LP_CPU_WAITI_RDY ro — need_des
0x198 LP_CPU_PWR1 access per field — need_des
  [31] LP_CPU_SLEEP_REQ wo — need_des
  [15:0] LP_CPU_WAKEUP_EN rw — need_des
0x19C HP_LP_CPU_COMM wo — need_des
  [31] HP_TRIGGER_LP — need_des
  [30] LP_TRIGGER_HP — need_des
0x1A0 HP_REGULATOR_CFG — need_des
  [31] DIG_REGULATOR_EN_CAL
0x1A4 MAIN_STATE ro reset 0x2180000 — need_des
  [31:25] MAIN_CUR_ST_STATE — need_des
  [24:18] MAIN_TAR_ST_STATE — need_des
  [17:11] MAIN_LAST_ST_STATE — need_des
0x1A8 PWR_STATE ro reset 0x802000 — need_des
  [31:23] HP_PWR_ST_STATE — need_des
  [22:18] LP_PWR_ST_STATE — need_des
  [17:13] BACKUP_ST_STATE — need_des
0x1AC CLK_STATE0 ro reset 0x80080000 — need_des
  [31] ANA_XPD_XTAL_STATE — need_des
  [30] ANA_XPD_BBPLL_STATE — need_des
  [29] ANA_XPD_BBPLL_I2C_STATE — need_des
  [28] ANA_XPD_BB_I2C_STATE — need_des
  [27] ANA_I2C_RETENTION_STATE — need_des
  [26] ANA_I2C_ISO_EN_STATE — need_des
  [25] ICG_GLOBAL_PLL_STATE — need_des
  [24] ICG_GLOBAL_XTAL_STATE — need_des
  [23] ICG_SLP_SEL_STATE — need_des
  [22:21] ICG_MODEM_CODE_STATE — need_des
  [20] ICG_MODEM_SWITCH_STATE — need_des
  [19] ICG_SYS_CLK_EN_STATE — need_des
  [18] SYS_CLK_NO_DIV_STATE — need_des
  [17:16] SYS_CLK_SEL_STATE — need_des
  [15] SYS_CLK_SLP_SEL_STATE — need_des
  [1] STABLE_XPD_XTAL_STATE — need_des
  [0] STABLE_XPD_BBPLL_STATE — need_des
0x1B0 CLK_STATE1 ro reset 0xFFFFFFFF — need_des
  [31:0] ICG_FUNC_EN_STATE
0x1B4 CLK_STATE2 ro reset 0xFFFFFFFF — need_des
  [31:0] ICG_APB_EN_STATE
0x1B8 DCM_CTRL access per field reset 0x44800001 — need_des
  [31] DCDC_RDY_CLR rw — need_des
  [30] DCDC_VCM_RDY ro — need_des
  [29] DCDC_CCM_RDY ro — need_des
  [28] DCDC_VCM_ENB rw — need_des
  [27] DCDC_CCM_SW_EN rw — need_des
  [26] DCDC_BIAS_CAL_DONE ro — need_des
  [25:23] DCDC_PCUR_LIMIT rw — need_des
  [22] DCDC_DCM_UPDATE wo — need_des
  [0] DSFMOS_USE_POR rw — need_des
0x1BC DCM_BOOST_CTRL reset 0xBA000000 — need_des
  [31:27] DCDC_BOOST_DREG — need_des
  [26] DCDC_BOOST_EN — need_des
  [25] DCDC_BOOST_CCM_ENB — need_des
  [24] DCDC_BOOST_CCM_CTRLEN — need_des
0x1C0 TOUCH_PWR_CTRL — need_des
  [31] TOUCH_FORCE_DONE — need_des
  [30] TOUCH_SLEEP_TIMER_EN — need_des
  [29:21] TOUCH_WAIT_CYCLES — need_des
  [15:0] TOUCH_SLEEP_CYCLES — need_des
0x1C4 BLE_BANDGAP_CTRL reset 0x3C000000 — need_des
  [31] EXT_FORCE_OCODE — need_des
  [30:23] EXT_OCODE — need_des
0x3FC DATE reset 0x2504280 — need_des
  [31] CLK_EN — need_des
  [30:0] PMU_DATE — need_des
